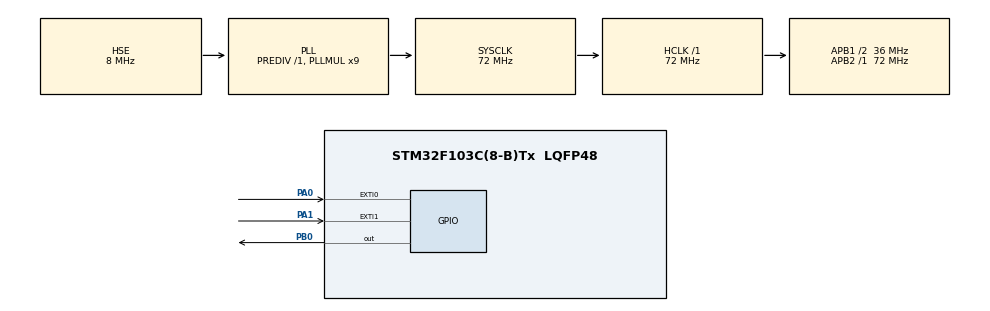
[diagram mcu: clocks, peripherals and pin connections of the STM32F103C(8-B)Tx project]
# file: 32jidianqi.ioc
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Mcu.Family=STM32F1
Mcu.Name=STM32F103C(8-B)Tx
Mcu.Package=LQFP48
NVIC.PriorityGroup=NVIC_PRIORITYGROUP_4
PA0-WKUP.GPIO_PuPd=GPIO_PULLDOWN
PA0-WKUP.Signal=GPXTI0
PA1.GPIO_PuPd=GPIO_PULLDOWN
PA1.Signal=GPXTI1
PA13.Mode=Serial_Wire
PA13.Signal=SYS_JTMS-SWDIO
PA14.Mode=Serial_Wire
PA14.Signal=SYS_JTCK-SWCLK
PB0.Signal=GPIO_Output
PD0-OSC_IN.Mode=HSE-External-Oscillator
PD0-OSC_IN.Signal=RCC_OSC_IN
PD1-OSC_OUT.Mode=HSE-External-Oscillator
PD1-OSC_OUT.Signal=RCC_OSC_OUT
ProjectManager.HeapSize=0x200
ProjectManager.StackSize=0x400
ProjectManager.TargetToolchain=MDK-ARM V5.32
RCC.AHBFreq_Value=72000000
RCC.APB1CLKDivider=RCC_HCLK_DIV2
RCC.APB1Freq_Value=36000000
RCC.APB1TimFreq_Value=72000000
RCC.APB2Freq_Value=72000000
RCC.APB2TimFreq_Value=72000000
RCC.EnbaleCSS=true
RCC.HCLKFreq_Value=72000000
RCC.PLLMUL=RCC_PLL_MUL9
RCC.PLLSourceVirtual=RCC_PLLSOURCE_HSE
RCC.SYSCLKFreq_VALUE=72000000
RCC.SYSCLKSource=RCC_SYSCLKSOURCE_PLLCLK
RCC.USBFreq_Value=72000000
board=custom

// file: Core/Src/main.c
/* USER CODE BEGIN Header */
/**
  ******************************************************************************
  * @file           : main.c
  * @brief          : Main program body
  ******************************************************************************
  * @attention
  *
  * Copyright (c) 2026 STMicroelectronics.
  * All rights reserved.
  *
  * This software is licensed under terms that can be found in the LICENSE file
  * in the root directory of this software component.
  * If no LICENSE file comes with this software, it is provided AS-IS.
  *
  ******************************************************************************
  */
/* USER CODE END Header */
#include "main.h"
#include "gpio.h"

/* USER CODE BEGIN PV */
#define INPUT_SAMPLE_MS          10U
#define STARTUP_LOCK_MS          2000U
#define HIGH_CONFIRM_SAMPLES    6U   /* 约60 ms高电平才认定有效 */
#define LOW_REARM_SAMPLES       12U  /* 约120 ms低电平后才重新使能 */
#define COMMAND_LOCKOUT_MS      400U

typedef struct
{
  uint8_t high_samples;
  uint8_t low_samples;
  uint8_t armed;
} PulseInputFilter;

static PulseInputFilter stop_filter = {0U, 0U, 0U};
static PulseInputFilter start_filter = {0U, 0U, 0U};
static uint32_t last_sample_tick = 0U;
static uint32_t startup_tick = 0U;
static uint32_t command_lockout_tick = 0U;
static uint16_t startup_low_samples = 0U;
static uint8_t startup_ready = 0U;
/* USER CODE END PV */

void SystemClock_Config(void);
/* USER CODE BEGIN PFP */
static uint8_t PulseInput_Update(PulseInputFilter *filter,
                                 GPIO_PinState raw_level);
static void ConveyorInputs_Process(void);
/* USER CODE END PFP */

/* USER CODE BEGIN 0 */

static uint8_t PulseInput_Update(PulseInputFilter *filter,
                                 GPIO_PinState raw_level)
{
  if (raw_level == GPIO_PIN_SET)
  {
    filter->low_samples = 0U;

    if (filter->armed == 0U)
    {
      return 0U;
    }

    if (filter->high_samples < HIGH_CONFIRM_SAMPLES)
    {
      filter->high_samples++;
    }

    if (filter->high_samples >= HIGH_CONFIRM_SAMPLES)
    {
      filter->high_samples = 0U;
      filter->armed = 0U;
      return 1U;
    }
  }
  else
  {
    filter->high_samples = 0U;

    if (filter->low_samples < LOW_REARM_SAMPLES)
    {
      filter->low_samples++;
    }

    if (filter->low_samples >= LOW_REARM_SAMPLES)
    {
      filter->low_samples = 0U;
      filter->armed = 1U;
    }
  }

  return 0U;
}

static void ConveyorInputs_Process(void)
{
  uint32_t now = HAL_GetTick();
  GPIO_PinState raw_stop;
  GPIO_PinState raw_start;
  uint8_t stop_event;
  uint8_t start_event;

  if ((uint32_t)(now - last_sample_tick) < INPUT_SAMPLE_MS)
  {
    return;
  }
  last_sample_tick = now;

  raw_stop = HAL_GPIO_ReadPin(GPIOA, GPIO_PIN_0);
  raw_start = HAL_GPIO_ReadPin(GPIOA, GPIO_PIN_1);

  /* 上电期间以及输入未回到双低前，强制保持停止。 */
  if (startup_ready == 0U)
  {
    HAL_GPIO_WritePin(GPIOB, GPIO_PIN_0, GPIO_PIN_RESET);
    if ((uint32_t)(now - startup_tick) < STARTUP_LOCK_MS)
    {
      return;
    }

    if ((raw_stop == GPIO_PIN_RESET) && (raw_start == GPIO_PIN_RESET))
    {
      if (startup_low_samples < LOW_REARM_SAMPLES)
      {
        startup_low_samples++;
      }
      if (startup_low_samples >= LOW_REARM_SAMPLES)
      {
        startup_ready = 1U;
        stop_filter.armed = 1U;
        start_filter.armed = 1U;
      }
    }
    else
    {
      startup_low_samples = 0U;
    }
    return;
  }

  if ((uint32_t)(now - command_lockout_tick) < COMMAND_LOCKOUT_MS)
  {
    return;
  }

  stop_event = PulseInput_Update(&stop_filter, raw_stop);
  start_event = PulseInput_Update(&start_filter, raw_start);

  /* 停止优先；双路同时触发时保持安全状态。 */
  if (stop_event != 0U)
  {
    HAL_GPIO_WritePin(GPIOB, GPIO_PIN_0, GPIO_PIN_RESET);
    command_lockout_tick = now;
  }
  else if ((start_event != 0U) &&
           (raw_stop == GPIO_PIN_RESET) &&
           (stop_filter.armed != 0U))
  {
    HAL_GPIO_WritePin(GPIOB, GPIO_PIN_0, GPIO_PIN_SET);
    command_lockout_tick = now;
  }
}

/* USER CODE END 0 */

int main(void)
{

  /* MCU Configuration--------------------------------------------------------*/

  /* Reset of all peripherals, Initializes the Flash interface and the Systick. */
  HAL_Init();

  /* Configure the system clock */
  SystemClock_Config();

  /* Initialize all configured peripherals */
  MX_GPIO_Init();
  /* USER CODE BEGIN 2 */
  /* Safe power-on state: keep the conveyor stopped until PA1 requests start. */
  HAL_GPIO_WritePin(GPIOB, GPIO_PIN_0, GPIO_PIN_RESET);
  startup_tick = HAL_GetTick();
  /* USER CODE END 2 */

  /* Infinite loop */
  while (1)
  {

    /* USER CODE BEGIN 3 */
    ConveyorInputs_Process();
  }
  /* USER CODE END 3 */
}

void SystemClock_Config(void)
{
  RCC_OscInitTypeDef RCC_OscInitStruct = {0};
  RCC_ClkInitTypeDef RCC_ClkInitStruct = {0};

  /** Initializes the RCC Oscillators according to the specified parameters
  * in the RCC_OscInitTypeDef structure.
  */
  RCC_OscInitStruct.OscillatorType = RCC_OSCILLATORTYPE_HSE;
  RCC_OscInitStruct.HSEState = RCC_HSE_ON;
  RCC_OscInitStruct.HSEPredivValue = RCC_HSE_PREDIV_DIV1;
  RCC_OscInitStruct.HSIState = RCC_HSI_ON;
  RCC_OscInitStruct.PLL.PLLState = RCC_PLL_ON;
  RCC_OscInitStruct.PLL.PLLSource = RCC_PLLSOURCE_HSE;
  RCC_OscInitStruct.PLL.PLLMUL = RCC_PLL_MUL9;
  if (HAL_RCC_OscConfig(&RCC_OscInitStruct) != HAL_OK)
  {
    Error_Handler();
  }

  /** Initializes the CPU, AHB and APB buses clocks
  */
  RCC_ClkInitStruct.ClockType = RCC_CLOCKTYPE_HCLK|RCC_CLOCKTYPE_SYSCLK
                              |RCC_CLOCKTYPE_PCLK1|RCC_CLOCKTYPE_PCLK2;
  RCC_ClkInitStruct.SYSCLKSource = RCC_SYSCLKSOURCE_PLLCLK;
  RCC_ClkInitStruct.AHBCLKDivider = RCC_SYSCLK_DIV1;
  RCC_ClkInitStruct.APB1CLKDivider = RCC_HCLK_DIV2;
  RCC_ClkInitStruct.APB2CLKDivider = RCC_HCLK_DIV1;

  if (HAL_RCC_ClockConfig(&RCC_ClkInitStruct, FLASH_LATENCY_2) != HAL_OK)
  {
    Error_Handler();
  }

  /** Enables the Clock Security System
  */
  HAL_RCC_EnableCSS();
}

/* USER CODE BEGIN 4 */
/* 传送带输入由主循环采样处理，不在 EXTI 中断中执行控制动作。 */
/* USER CODE END 4 */

void Error_Handler(void)
{
  __disable_irq();
  while (1)
  {
  }
}
